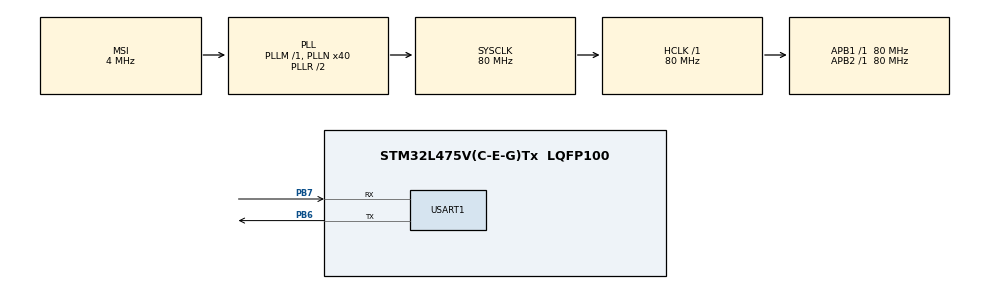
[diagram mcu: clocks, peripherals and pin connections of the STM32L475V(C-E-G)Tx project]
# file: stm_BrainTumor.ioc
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Dma.Request0=USART1_RX
Dma.USART1_RX.0.Direction=DMA_PERIPH_TO_MEMORY
Dma.USART1_RX.0.Instance=DMA1_Channel5
Dma.USART1_RX.0.MemDataAlignment=DMA_MDATAALIGN_BYTE
Dma.USART1_RX.0.MemInc=DMA_MINC_ENABLE
Dma.USART1_RX.0.Mode=DMA_CIRCULAR
Dma.USART1_RX.0.PeriphDataAlignment=DMA_PDATAALIGN_BYTE
Dma.USART1_RX.0.PeriphInc=DMA_PINC_DISABLE
Dma.USART1_RX.0.Priority=DMA_PRIORITY_LOW
Mcu.Family=STM32L4
Mcu.Name=STM32L475V(C-E-G)Tx
Mcu.Package=LQFP100
NVIC.DMA1_Channel5_IRQn=true\:0\:0\:false\:false\:true\:false\:true\:true
NVIC.PriorityGroup=NVIC_PRIORITYGROUP_4
PA13\ (JTMS-SWDIO).Mode=Serial_Wire
PA13\ (JTMS-SWDIO).Signal=SYS_JTMS-SWDIO
PA14\ (JTCK-SWCLK).Mode=Serial_Wire
PA14\ (JTCK-SWCLK).Signal=SYS_JTCK-SWCLK
PB6.Mode=Asynchronous
PB6.Signal=USART1_TX
PB7.Mode=Asynchronous
PB7.Signal=USART1_RX
PC14-OSC32_IN\ (PC14).Mode=LSE-External-Oscillator
PC14-OSC32_IN\ (PC14).Signal=RCC_OSC32_IN
PC15-OSC32_OUT\ (PC15).Mode=LSE-External-Oscillator
PC15-OSC32_OUT\ (PC15).Signal=RCC_OSC32_OUT
ProjectManager.HeapSize=0x800
ProjectManager.StackSize=0x800
ProjectManager.TargetToolchain=STM32CubeIDE
RCC.ADCFreq_Value=48000000
RCC.AHBFreq_Value=80000000
RCC.APB1Freq_Value=80000000
RCC.APB1TimFreq_Value=80000000
RCC.APB2Freq_Value=80000000
RCC.APB2TimFreq_Value=80000000
RCC.CortexFreq_Value=80000000
RCC.HCLKFreq_Value=80000000
RCC.HSE_VALUE=8000000
RCC.HSI_VALUE=16000000
RCC.MSI_VALUE=4000000
RCC.PLLN=40
RCC.PLLSAI1N=24
RCC.SYSCLKFreq_VALUE=80000000
RCC.SYSCLKSource=RCC_SYSCLKSOURCE_PLLCLK
RCC.USBFreq_Value=48000000
RCC.VCOOutputFreq_Value=160000000
STMicroelectronics.X-CUBE-AI.8.1.0.ActivationBufferSizeList=65532
STMicroelectronics.X-CUBE-AI.8.1.0.ActivationBuffers=pool0
STMicroelectronics.X-CUBE-AI.8.1.0.ActivationNames=pool0
STMicroelectronics.X-CUBE-AI.8.1.0.ActivationSizes=AI_NETWORK_DATA_ACTIVATION_1_SIZE
STMicroelectronics.X-CUBE-AI.8.1.0.HeapSize=0x800
STMicroelectronics.X-CUBE-AI.8.1.0.InternalRamActivationBufferMaxSize=AI_NETWORK_DATA_ACTIVATIONS_SIZE
STMicroelectronics.X-CUBE-AI.8.1.0.LatestDirectoryUsed-618d447772b81111cd2daa3e9d671ef6139eb59a7579e16a18916affb902466a=C\:\\Users\\Latitude 7280\\Downloads
STMicroelectronics.X-CUBE-AI.8.1.0.MaximumNumberOfInputLayer=1
STMicroelectronics.X-CUBE-AI.8.1.0.MaximumNumberOfOutputLayer=1
STMicroelectronics.X-CUBE-AI.8.1.0.MaximumSizeOfInputLayer=1
STMicroelectronics.X-CUBE-AI.8.1.0.MaximumSizeOfOutputLayer=1
STMicroelectronics.X-CUBE-AI.8.1.0.ModelActualCompression-618d447772b81111cd2daa3e9d671ef6139eb59a7579e16a18916affb902466a=0.0
STMicroelectronics.X-CUBE-AI.8.1.0.ModelCompression-618d447772b81111cd2daa3e9d671ef6139eb59a7579e16a18916affb902466a=None
STMicroelectronics.X-CUBE-AI.8.1.0.ModelFlashOccupation-618d447772b81111cd2daa3e9d671ef6139eb59a7579e16a18916affb902466a=864764
STMicroelectronics.X-CUBE-AI.8.1.0.ModelHashList=618d447772b81111cd2daa3e9d671ef6139eb59a7579e16a18916affb902466a
STMicroelectronics.X-CUBE-AI.8.1.0.ModelKind-618d447772b81111cd2daa3e9d671ef6139eb59a7579e16a18916affb902466a=TFLITE
STMicroelectronics.X-CUBE-AI.8.1.0.ModelMacc-618d447772b81111cd2daa3e9d671ef6139eb59a7579e16a18916affb902466a=1699422
STMicroelectronics.X-CUBE-AI.8.1.0.ModelName-618d447772b81111cd2daa3e9d671ef6139eb59a7579e16a18916affb902466a=network
STMicroelectronics.X-CUBE-AI.8.1.0.ModelNameList=network
STMicroelectronics.X-CUBE-AI.8.1.0.ModelRamOccupation-618d447772b81111cd2daa3e9d671ef6139eb59a7579e16a18916affb902466a=65532
STMicroelectronics.X-CUBE-AI.8.1.0.ModelStructureFile-618d447772b81111cd2daa3e9d671ef6139eb59a7579e16a18916affb902466a=C\:\\Users\\Latitude 7280\\Downloads\\bt_55_model.tflite
STMicroelectronics.X-CUBE-AI.8.1.0.ModelType-618d447772b81111cd2daa3e9d671ef6139eb59a7579e16a18916affb902466a=STM32Cube.AI runtime
STMicroelectronics.X-CUBE-AI.8.1.0.ReadyForCodeGeneration=true
STMicroelectronics.X-CUBE-AI.8.1.0.StackSize=0x800
STMicroelectronics.X-CUBE-AI.8.1.0.WorkingBufferStartAddrList=0xFFFFFFFF
STMicroelectronics.X-CUBE-AI.8.1.0.XAaCUBEAaAICcArtificialOoIntelligenceJjCore=true
STMicroelectronics.X-CUBE-AI.8.1.0.copyWeightToRam=false
STMicroelectronics.X-CUBE-AI.8.1.0.customLayerConfigEnabled=false
STMicroelectronics.X-CUBE-AI.8.1.0.noOnnxIoTranspose=false
STMicroelectronics.X-CUBE-AI.8.1.0.useInputAllocation=true
STMicroelectronics.X-CUBE-AI.8.1.0.useOutputAllocation=true
USART1.VirtualMode-Asynchronous=VM_ASYNC
VP_CRC_VS_CRC.Mode=CRC_Activate
VP_STMicroelectronics.X-CUBE-AI_VS_ArtificialOoIntelligenceJjXAaCUBEAaAI_8.1.0.Mode=ArtificialOoIntelligenceJjXAaCUBEAaAI
board=B-L475E-IOT01A1

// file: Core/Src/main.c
/* USER CODE BEGIN Header */
/**
  ******************************************************************************
  * @file           : main.c
  * @brief          : Main program body
  ******************************************************************************
  * @attention
  *
  * Copyright (c) 2024 STMicroelectronics.
  * All rights reserved.
  *
  * This software is licensed under terms that can be found in the LICENSE file
  * in the root directory of this software component.
  * If no LICENSE file comes with this software, it is provided AS-IS.
  *
  ******************************************************************************
  */
/* USER CODE END Header */
#include "main.h"

/* USER CODE BEGIN Includes */

#include <stdio.h>
#include <string.h>
#include <stdlib.h>
#include "ai_platform.h"
#include "network.h"
#include "network_data.h"

/* USER CODE END Includes */

CRC_HandleTypeDef hcrc;

UART_HandleTypeDef huart1;
DMA_HandleTypeDef hdma_usart1_rx;

/* USER CODE BEGIN PV */

uint8_t txdata_0[1] = "0";
uint8_t txdata_1[1] = "1";
uint8_t txdata_2[1] = "2";
uint8_t txdata_3[1] = "3";

uint8_t rxdata[3025];

ai_handle network;
float aiInData[AI_NETWORK_IN_1_SIZE];
float aiOutData[AI_NETWORK_OUT_1_SIZE];
ai_u8 activations[AI_NETWORK_DATA_ACTIVATIONS_SIZE];
const char* activities[AI_NETWORK_OUT_1_SIZE] = {
  "Normal", "Glioma", "Meningioma","Pituitary"
};
ai_buffer * ai_input;
ai_buffer * ai_output;

/* USER CODE END PV */

void SystemClock_Config(void);
static void MX_GPIO_Init(void);
static void MX_DMA_Init(void);
static void MX_USART1_UART_Init(void);
static void MX_CRC_Init(void);
/* USER CODE BEGIN PFP */

static void AI_Init(void);
static void AI_Run(float *pIn, float *pOut);
static uint32_t argmax(const float * values, uint32_t len);
static void copyToFloat(float aiInData[], uint8_t rxdata[]);

/* USER CODE END PFP */

int main(void)
{

  /* MCU Configuration--------------------------------------------------------*/

  /* Reset of all peripherals, Initializes the Flash interface and the Systick. */
  HAL_Init();

  /* Configure the system clock */
  SystemClock_Config();

  /* Initialize all configured peripherals */
  MX_GPIO_Init();
  MX_DMA_Init();
  MX_USART1_UART_Init();
  MX_CRC_Init();
  /* USER CODE BEGIN 2 */
  HAL_UART_Init(&huart1);
  AI_Init();
  HAL_UART_Receive_DMA(&huart1, (uint8_t*)rxdata, sizeof(rxdata));
  /* USER CODE END 2 */

  /* Infinite loop */
  /* USER CODE BEGIN WHILE */
  //uint32_t index = 0;
  while (1)
  {
    /* USER CODE END WHILE */

  }
}

void SystemClock_Config(void)
{
  RCC_OscInitTypeDef RCC_OscInitStruct = {0};
  RCC_ClkInitTypeDef RCC_ClkInitStruct = {0};

  /** Configure the main internal regulator output voltage
  */
  if (HAL_PWREx_ControlVoltageScaling(PWR_REGULATOR_VOLTAGE_SCALE1) != HAL_OK)
  {
    Error_Handler();
  }

  /** Configure LSE Drive Capability
  */
  HAL_PWR_EnableBkUpAccess();
  __HAL_RCC_LSEDRIVE_CONFIG(RCC_LSEDRIVE_LOW);

  /** Initializes the RCC Oscillators according to the specified parameters
  * in the RCC_OscInitTypeDef structure.
  */
  RCC_OscInitStruct.OscillatorType = RCC_OSCILLATORTYPE_LSE|RCC_OSCILLATORTYPE_MSI;
  RCC_OscInitStruct.LSEState = RCC_LSE_ON;
  RCC_OscInitStruct.MSIState = RCC_MSI_ON;
  RCC_OscInitStruct.MSICalibrationValue = 0;
  RCC_OscInitStruct.MSIClockRange = RCC_MSIRANGE_6;
  RCC_OscInitStruct.PLL.PLLState = RCC_PLL_ON;
  RCC_OscInitStruct.PLL.PLLSource = RCC_PLLSOURCE_MSI;
  RCC_OscInitStruct.PLL.PLLM = 1;
  RCC_OscInitStruct.PLL.PLLN = 40;
  RCC_OscInitStruct.PLL.PLLP = RCC_PLLP_DIV7;
  RCC_OscInitStruct.PLL.PLLQ = RCC_PLLQ_DIV2;
  RCC_OscInitStruct.PLL.PLLR = RCC_PLLR_DIV2;
  if (HAL_RCC_OscConfig(&RCC_OscInitStruct) != HAL_OK)
  {
    Error_Handler();
  }

  /** Initializes the CPU, AHB and APB buses clocks
  */
  RCC_ClkInitStruct.ClockType = RCC_CLOCKTYPE_HCLK|RCC_CLOCKTYPE_SYSCLK
                              |RCC_CLOCKTYPE_PCLK1|RCC_CLOCKTYPE_PCLK2;
  RCC_ClkInitStruct.SYSCLKSource = RCC_SYSCLKSOURCE_PLLCLK;
  RCC_ClkInitStruct.AHBCLKDivider = RCC_SYSCLK_DIV1;
  RCC_ClkInitStruct.APB1CLKDivider = RCC_HCLK_DIV1;
  RCC_ClkInitStruct.APB2CLKDivider = RCC_HCLK_DIV1;

  if (HAL_RCC_ClockConfig(&RCC_ClkInitStruct, FLASH_LATENCY_4) != HAL_OK)
  {
    Error_Handler();
  }

  /** Enable MSI Auto calibration
  */
  HAL_RCCEx_EnableMSIPLLMode();
}

static void MX_CRC_Init(void)
{

  hcrc.Instance = CRC;
  hcrc.Init.DefaultPolynomialUse = DEFAULT_POLYNOMIAL_ENABLE;
  hcrc.Init.DefaultInitValueUse = DEFAULT_INIT_VALUE_ENABLE;
  hcrc.Init.InputDataInversionMode = CRC_INPUTDATA_INVERSION_NONE;
  hcrc.Init.OutputDataInversionMode = CRC_OUTPUTDATA_INVERSION_DISABLE;
  hcrc.InputDataFormat = CRC_INPUTDATA_FORMAT_BYTES;
  if (HAL_CRC_Init(&hcrc) != HAL_OK)
  {
    Error_Handler();
  }

}

static void MX_USART1_UART_Init(void)
{

  huart1.Instance = USART1;
  huart1.Init.BaudRate = 115200;
  huart1.Init.WordLength = UART_WORDLENGTH_8B;
  huart1.Init.StopBits = UART_STOPBITS_1;
  huart1.Init.Parity = UART_PARITY_NONE;
  huart1.Init.Mode = UART_MODE_TX_RX;
  huart1.Init.HwFlowCtl = UART_HWCONTROL_NONE;
  huart1.Init.OverSampling = UART_OVERSAMPLING_16;
  huart1.Init.OneBitSampling = UART_ONE_BIT_SAMPLE_DISABLE;
  huart1.AdvancedInit.AdvFeatureInit = UART_ADVFEATURE_NO_INIT;
  if (HAL_UART_Init(&huart1) != HAL_OK)
  {
    Error_Handler();
  }

}

static void MX_DMA_Init(void)
{

  /* DMA controller clock enable */
  __HAL_RCC_DMA1_CLK_ENABLE();

  /* DMA interrupt init */
  /* DMA1_Channel5_IRQn interrupt configuration */
  HAL_NVIC_SetPriority(DMA1_Channel5_IRQn, 0, 0);
  HAL_NVIC_EnableIRQ(DMA1_Channel5_IRQn);

}

static void MX_GPIO_Init(void)
{

  /* GPIO Ports Clock Enable */
  __HAL_RCC_GPIOC_CLK_ENABLE();
  __HAL_RCC_GPIOA_CLK_ENABLE();
  __HAL_RCC_GPIOB_CLK_ENABLE();

}

/* USER CODE BEGIN 4 */

void HAL_UART_RxHalfCpltCallback(UART_HandleTypeDef *huart)
{
	copyToFloat(aiInData,rxdata);
	AI_Run(aiInData, aiOutData);
	uint32_t class = argmax(aiOutData, AI_NETWORK_OUT_1_SIZE);
	printf("%s\r\n", activities[class]);
	HAL_UART_Transmit(&huart1, txdata_1, sizeof(txdata_1), 200);
}

int _write(int fd, char * ptr, int len)
{
  HAL_UART_Transmit(&huart1, (uint8_t *) ptr, len, HAL_MAX_DELAY);
  return len;
}

static void AI_Init(void)
{
  ai_error err;

  /* Create a local array with the addresses of the activations buffers */
  const ai_handle act_addr[] = { activations };
  /* Create an instance of the model */
  err = ai_network_create_and_init(&network, act_addr, NULL);
  if (err.type != AI_ERROR_NONE) {
    printf("ai_network_create error - type=%d code=%d\r\n", err.type, err.code);
    Error_Handler();
  }
  ai_input = ai_network_inputs_get(network, NULL);
  ai_output = ai_network_outputs_get(network, NULL);
}

static void AI_Run(float *pIn, float *pOut)
{
  ai_i32 batch;
  ai_error err;

  /* Update IO handlers with the data payload */
  ai_input[0].data = AI_HANDLE_PTR(pIn);
  ai_output[0].data = AI_HANDLE_PTR(pOut);

  batch = ai_network_run(network, ai_input, ai_output);
  if (batch != 1) {
    err = ai_network_get_error(network);
    printf("AI ai_network_run error - type=%d code=%d\r\n", err.type, err.code);
    Error_Handler();
  }
}

static uint32_t argmax(const float * values, uint32_t len)
{
  float max_value = values[0];
  uint32_t max_index = 0;
  for (uint32_t i = 1; i < len; i++) {
    if (values[i] > max_value) {
      max_value = values[i];
      max_index = i;
    }
  }
  return max_index;
}

static void copyToFloat(float aiInData[], uint8_t rxdata[]){
	for(int i = 0; i < 3025; i++){
		aiInData[i] = rxdata[i];
	}
}

/* USER CODE END 4 */

void Error_Handler(void)
{
  __disable_irq();
  while (1)
  {
  }
}
